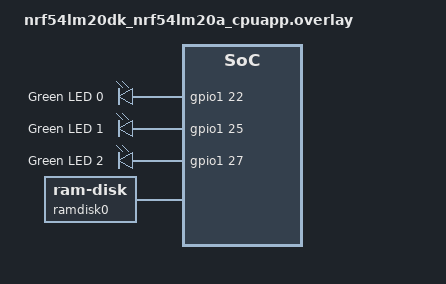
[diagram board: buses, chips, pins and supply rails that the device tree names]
/*
 * Copyright (c) 2026 Nordic Semiconductor ASA
 *
 * SPDX-License-Identifier: LicenseRef-Nordic-5-Clause
 */

#include "common/usb_audio.dtsi"

/ {
	audioleds: audioleds {
		compatible = "gpio-leds";
		status = "okay";

		led_conn_status: led_conn_status {
			gpios = <&gpio1 22 GPIO_ACTIVE_HIGH>;
			label = "Green LED 0";
		};

		led_sync_status: led_sync_status {
			gpios = <&gpio1 25 GPIO_ACTIVE_HIGH>;
			label = "Green LED 1";
		};

		led_app_status: led_app_status {
			gpios = <&gpio1 27 GPIO_ACTIVE_HIGH>;
			label = "Green LED 2";
		};
	};

	ramdisk0: ramdisk0 {
		compatible = "zephyr,ram-disk";
		disk-name = "RAM";
		sector-size = <512>;
		sector-count = <80>;
	};
};
